# ATtiny3227 device description
Architecture: AVR8X; Family: tinyAVR 2
Registers are 8-bit, read-write, reset 0x0 unless marked. A register's access mark holds for its fields unless they carry their own. Offsets are from the block's base; [hi:lo] are bit positions; {n}, {i} and the like mark numbered series.

## GPIO — General Purpose I/O Register
Instances: GPIO 0x001C
{0x0+i} GPIOR{i} reset not defined (i=0..3) — General Purpose IO Register {i}

## LOCKBIT
Instances: LOCKBIT 0x128A
0x00 LOCKBIT reset 0xC5 — Lock Bits
  [7:0] LB
    58=RWLOCK (Read and write lock); 197=NOLOCK (No locks)

## NVMCTRL — Non-volatile Memory Controller
Instances: NVMCTRL 0x1000
0x00 CTRLA — Control A
  [2:0] CMD — Command
    0=NONE (No Command); 1=PAGEWRITE (Write page); 2=PAGEERASE (Erase page); 3=PAGEERASEWRITE (Erase and write page); 4=PAGEBUFCLR (Page buffer clear); 5=CHIPERASE; 6=EEERASE (EEPROM erase); 7=FUSEWRITE (Write fuse (PDI only))
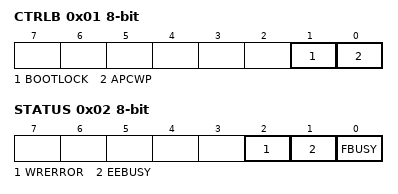
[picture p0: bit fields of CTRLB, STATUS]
0x01 CTRLB — Control B
  [1] BOOTLOCK
  [0] APCWP — Application code write protect
0x02 STATUS ro
  [2] WRERROR — Write error
  [1] EEBUSY — EEPROM busy
  [0] FBUSY — Flash busy
0x03 INTCTRL — Interrupt Control
  [0] EEREADY — EEPROM Ready
0x04 INTFLAGS — Interrupt Flags
  [0] EEREADY — EEPROM Ready
0x06 DATA 16-bit reset not defined
0x08 ADDR 16-bit reset not defined — Address

## PORT — I/O Ports
Instances: PORTA 0x0400, PORTB 0x0420, PORTC 0x0440
0x00 DIR reset not defined — Data Direction
0x01 DIRSET reset not defined — Data Direction Set
0x02 DIRCLR reset not defined — Data Direction Clear
0x03 DIRTGL reset not defined — Data Direction Toggle
0x04 OUT reset not defined — Output Value
0x05 OUTSET reset not defined — Output Value Set
0x06 OUTCLR reset not defined — Output Value Clear
0x07 OUTTGL reset not defined — Output Value Toggle
0x08 IN reset not defined — Input Value
0x09 INTFLAGS — Interrupt Flags
  [7:0] INT — Pin Interrupt
0x0A PORTCTRL — Port Control
  [0] SRL — Slew Rate Limit Enable
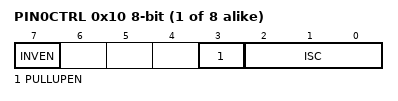
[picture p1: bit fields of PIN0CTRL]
{0x10+i} PIN{i}CTRL (i=0..7) — Pin {i} Control
  [7] INVEN — Inverted I/O Enable
  [3] PULLUPEN — Pullup enable
  [2:0] ISC — Input/Sense Configuration
    0=INTDISABLE (Interrupt disabled but input buffer enabled); 1=BOTHEDGES (Sense Both Edges); 2=RISING (Sense Rising Edge); 3=FALLING (Sense Falling Edge); 4=INPUT_DISABLE (Digital Input Buffer disabled); 5=LEVEL (Sense low Level)

## PORTMUX — Port Multiplexer
Instances: PORTMUX 0x05E0
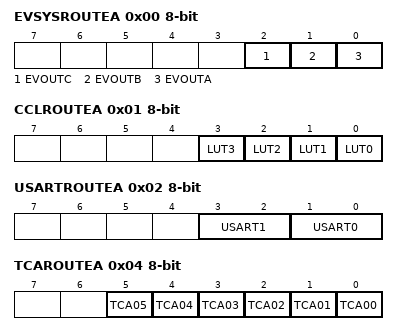
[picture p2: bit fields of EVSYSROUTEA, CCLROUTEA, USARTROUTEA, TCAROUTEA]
0x00 EVSYSROUTEA — Port Multiplexer EVSYS
  [2] EVOUTC — Event Output C
    0=DEFAULT (EVOUTC: PC2)
  [1] EVOUTB — Event Output B
    0=DEFAULT (EVOUTB: PB2); 1=ALT1 (EVOUTB: PB7)
  [0] EVOUTA — Event Output A
    0=DEFAULT (EVOUTA: PA2); 1=ALT1 (EVOUTA: PA7)
0x01 CCLROUTEA — Port Multiplexer CCL
  [3] LUT3 — CCL LUT3
    0=DEFAULT (INn: PC0, PC1, PC2. OUT: PC4.); 1=ALT1 (INn: PC0, PC1, PC2. OUT: PA5.)
  [2] LUT2 — CCL LUT2
    0=DEFAULT (INn: PB0, PB1, PB2. OUT: PB3.); 1=ALT1 (INn: PB0, PB1, PB2. OUT: PB6.)
  [1] LUT1 — CCL LUT1
    0=DEFAULT (INn: PC3, PC4, PC5. OUT: PA7.); 1=ALT1 (INn: PC3, PC4, PC5. OUT: PC1.)
  [0] LUT0 — CCL LUT0
    0=DEFAULT (INn: PA0, PA1, PA2. OUT: PA4.); 1=ALT1 (INn: PA0, PA1, PA2. OUT: PB4.)
0x02 USARTROUTEA — Port Multiplexer USART register A
  [3:2] USART1 — Port Multiplexer USART1
    0=DEFAULT (TxD: PA1, RxD: PA2, XCK: PA3, XDIR: PA4); 1=ALT1 (TxD: PC2, RxD: PC1, XCK: PC0, XDIR: PC3); 3=NONE (Not connected to any pins)
  [1:0] USART0 — Port Multiplexer USART0
    0=DEFAULT (TxD: PB2, RxD: PB3, XCK: PB1, XDIR: PB0); 1=ALT1 (TxD: PA1, RxD: PA2, XCK: PA3, XDIR: PA4); 3=NONE (Not connected to any pins)
0x03 SPIROUTEA — Port Multiplexer TWI and SPI
  [1:0] SPI0 — Port Multiplexer SPI0
    0=DEFAULT (MOSI: PA1, MISO: PA2, SCK: PA3, SS: PA4); 1=ALT1 (MOSI: PC2, MISO: PC1, SCK: PC0, SS: PC3); 3=NONE (Not connected to any pins)
0x04 TCAROUTEA — Port Multiplexer TCA
  [5] TCA05 — Port Multiplexer TCA0 Output 5
    0=DEFAULT (WO5: PA5); 1=ALT1 (WO5: PC5)
  [4] TCA04 — Port Multiplexer TCA0 Output 4
    0=DEFAULT (WO4: PA4); 1=ALT1 (WO4: PC4)
  [3] TCA03 — Port Multiplexer TCA0 Output 3
    0=DEFAULT (WO3: PA3); 1=ALT1 (WO3: PC3)
  [2] TCA02 — Port Multiplexer TCA0 Output 2
    0=DEFAULT (WO2: PB2); 1=ALT1 (WO2: PB5)
  [1] TCA01 — Port Multiplexer TCA0 Output 1
    0=DEFAULT (WO1: PB1); 1=ALT1 (WO1: PB4)
  [0] TCA00 — Port Multiplexer TCA0 Output 0
    0=DEFAULT (WO0: PB0); 1=ALT1 (WO0: PB3)
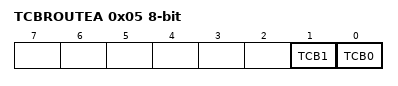
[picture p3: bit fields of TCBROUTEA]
0x05 TCBROUTEA — Port Multiplexer TCB
  [1] TCB1 — Port Multiplexer TCB1
    0=DEFAULT (WO: PA3); 1=ALT1 (WO: PC4)
  [0] TCB0 — Port Multiplexer TCB0
    0=DEFAULT (WO: PA5); 1=ALT1 (WO: PC0)
